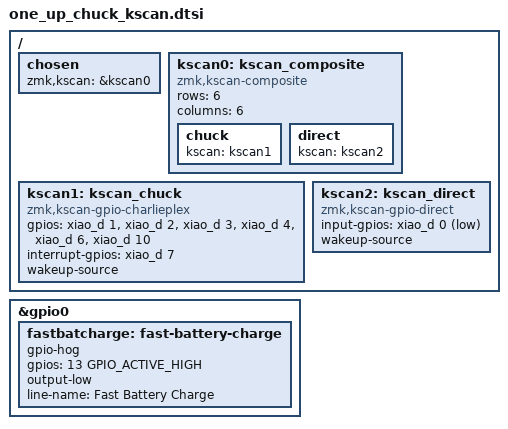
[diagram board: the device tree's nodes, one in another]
/ {
    chosen {
        zmk,kscan = &kscan0;
    };

    kscan0: kscan_composite {
        compatible = "zmk,kscan-composite";
        rows = <6>;
        columns = <6>;

        chuck {
            kscan = <&kscan1>;
        };

        direct {
            kscan = <&kscan2>;
        };
    };

    kscan1: kscan_chuck {
        compatible = "zmk,kscan-gpio-charlieplex";

        gpios
            = <&xiao_d 1 GPIO_ACTIVE_HIGH>
            , <&xiao_d 2 GPIO_ACTIVE_HIGH>
            , <&xiao_d 3 GPIO_ACTIVE_HIGH>
            , <&xiao_d 4 GPIO_ACTIVE_HIGH>
            , <&xiao_d 6 GPIO_ACTIVE_HIGH>
            , <&xiao_d 10 GPIO_ACTIVE_HIGH>
            ;

        interrupt-gpios = <&xiao_d 7 (GPIO_ACTIVE_HIGH | GPIO_PULL_DOWN)>;

        wakeup-source;
    };

    kscan2: kscan_direct {
        compatible = "zmk,kscan-gpio-direct";

        input-gpios = <&xiao_d 0 (GPIO_ACTIVE_LOW | GPIO_PULL_UP)>;

        wakeup-source;
    };
};

// For bigger batteries, we want to enable faster charging
&gpio0 {
    fastbatcharge: fast-battery-charge {
        gpio-hog;
        gpios = <13 GPIO_ACTIVE_HIGH>;
        output-low;
        line-name = "Fast Battery Charge";
    };
};

// vim: expandtab softtabstop=4 shiftwidth=4
